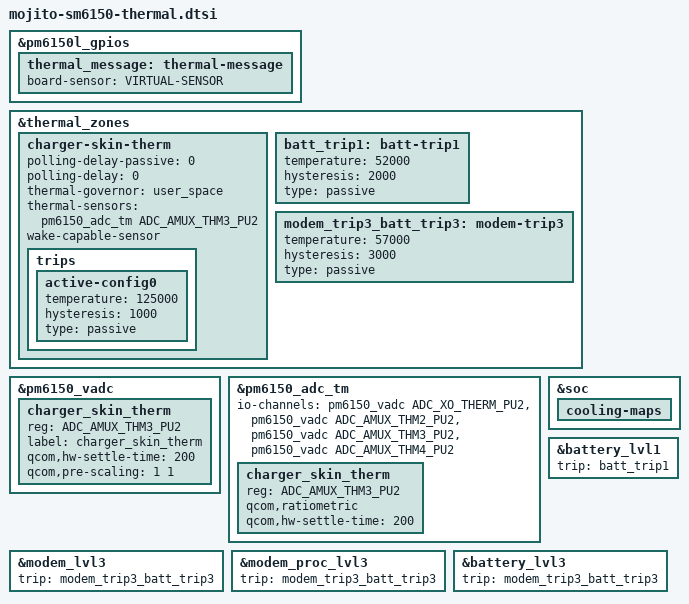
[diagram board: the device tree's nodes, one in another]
/*
 * Copyright (c) 2019, The Linux Foundation. All rights reserved.
 * Copyright (C) 2021 XiaoMi, Inc.
 *
 * This program is free software; you can redistribute it and/or modify
 * it under the terms of the GNU General Public License version 2 and
 * only version 2 as published by the Free Software Foundation.
 *
 * This program is distributed in the hope that it will be useful,
 * but WITHOUT ANY WARRANTY; without even the implied warranty of
 * MERCHANTABILITY or FITNESS FOR A PARTICULAR PURPOSE.  See the
 * GNU General Public License for more details.
 */

&pm6150l_gpios {
	thermal_message: thermal-message {
		board-sensor = "VIRTUAL-SENSOR";
	};
};

&thermal_zones {
	/delete-node/ modem_trip3_batt_trip1;
	/delete-node/ batt_trip3;

	charger-skin-therm {
		polling-delay-passive = <0>;
		polling-delay = <0>;
		thermal-governor = "user_space";
		thermal-sensors = <&pm6150_adc_tm ADC_AMUX_THM3_PU2>;
		wake-capable-sensor;
			trips {
				active-config0 {
				temperature = <125000>;
				hysteresis = <1000>;
				type = "passive";
			};
		};
	};

	batt_trip1: batt-trip1 {
		temperature = <52000>;
		hysteresis = <2000>;
		type = "passive";
	};

	modem_trip3_batt_trip3: modem-trip3 {
		temperature = <57000>;
		hysteresis = <3000>;
		type = "passive";
	};
};

&pm6150_vadc {
	charger_skin_therm {
		reg = <ADC_AMUX_THM3_PU2>;
		label = "charger_skin_therm";
		qcom,hw-settle-time = <200>;
		qcom,pre-scaling = <1 1>;
	};
};

&pm6150_adc_tm {
	io-channels = <&pm6150_vadc ADC_XO_THERM_PU2>,
			<&pm6150_vadc ADC_AMUX_THM2_PU2>,
			<&pm6150_vadc ADC_AMUX_THM3_PU2>,
			<&pm6150_vadc ADC_AMUX_THM4_PU2>;

	charger_skin_therm {
		reg = <ADC_AMUX_THM3_PU2>;
		qcom,ratiometric;
		qcom,hw-settle-time = <200>;
	};
};

&soc {
	cooling-maps {
		/delete-node/ skin_cpu6;
		/delete-node/ skin_cpu0;
	};
};

&modem_lvl3 {
	trip = <&modem_trip3_batt_trip3>;
};

&modem_proc_lvl3 {
	trip = <&modem_trip3_batt_trip3>;
};

&battery_lvl1 {
	trip = <&batt_trip1>;
};

&battery_lvl3 {
	trip = <&modem_trip3_batt_trip3>;
};
